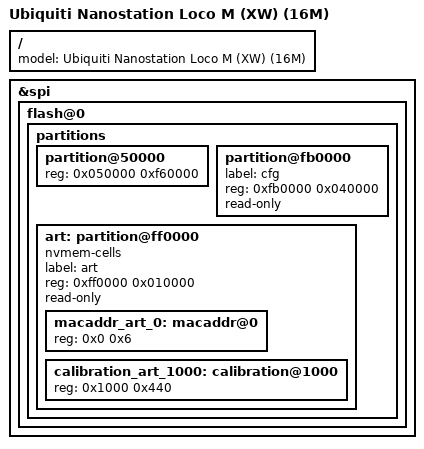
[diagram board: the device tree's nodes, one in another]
// SPDX-License-Identifier: GPL-2.0-or-later OR MIT

#include "ar9342_ubnt_nanostation-loco-m-xw.dts"

/ {
	model = "Ubiquiti Nanostation Loco M (XW) (16M)";
};


&spi {
	status = "okay";

	flash@0 {
		partitions {
			partition@50000 {
				reg = <0x050000 0xf60000>;
			};

			/delete-node/ partition@7b0000;
			partition@fb0000 {
				label = "cfg";
				reg = <0xfb0000 0x040000>;
				read-only;
			};

			/delete-node/ partition@7f0000;
			art: partition@ff0000 {
				label = "art";
				reg = <0xff0000 0x010000>;
				read-only;

				compatible = "nvmem-cells";
				#address-cells = <1>;
				#size-cells = <1>;

				macaddr_art_0: macaddr@0 {
					reg = <0x0 0x6>;
				};

				calibration_art_1000: calibration@1000 {
					reg = <0x1000 0x440>;
				};
			};
		};
	};
};
